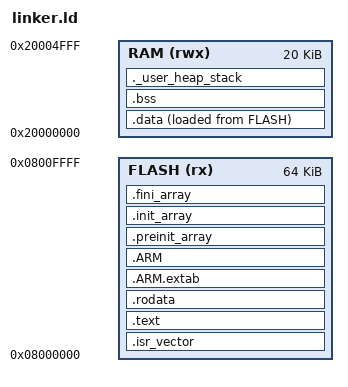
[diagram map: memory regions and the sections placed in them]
/* #######################################################################
 * linker.ld - STM32F103C8T6 链接脚本
 * #######################################################################
 *
 * 内存布局:
 *   Flash (ROM): 64KB, 起始地址 0x08000000
 *   SRAM (RAM):  20KB, 起始地址 0x20000000
 *
 * 启动流程:
 *   1. CPU 从 0x08000000 读取初始栈指针 (MSP)
 *   2. CPU 从 0x08000004 读取复位向量 (Reset_Handler)
 *   3. Reset_Handler 拷贝 .data 段, 清零 .bss 段, 跳转 main()
 *
 * ####################################################################### */

/* =======================================================================
 * 入口点定义
 * ======================================================================= */

ENTRY(Reset_Handler)

/* =======================================================================
 * 内存区域定义
 * ======================================================================= */

MEMORY
{
    FLASH (rx)  : ORIGIN = 0x08000000, LENGTH = 64K
    RAM   (rwx) : ORIGIN = 0x20000000, LENGTH = 20K
}

/* =======================================================================
 * 栈和堆配置
 * ======================================================================= */

/* 栈顶地址 (RAM 最高地址, 向下增长) */
_estack = ORIGIN(RAM) + LENGTH(RAM);

/* 栈大小 (1KB) */
__Stack_Size = 1024;
__Stack_Limit = _estack - __Stack_Size;

/* 堆大小 (0B - 不使用堆) */
__Heap_Size = 0;
_end = __Stack_Limit - __Heap_Size;

/* =======================================================================
 * 段布局定义
 * ======================================================================= */

SECTIONS
{
    /* -------------------------------------------------------------------
     * .isr_vector 段 - 中断向量表
     *
     * 必须放在 Flash 最开头 (0x08000000)
     * ------------------------------------------------------------------- */
    .isr_vector :
    {
        . = ALIGN(4);
        KEEP(*(.isr_vector))      /* 保留向量表, 不被优化掉 */
        . = ALIGN(4);
    } > FLASH

    /* -------------------------------------------------------------------
     * .text 段 - 代码和只读数据
     * ------------------------------------------------------------------- */
    .text :
    {
        . = ALIGN(4);
        *(.text)                  /* 普通代码 */
        *(.text*)                 /* 模板和内联代码 */
        *(.glue_7)                /* ARM/Thumb 互调用粘合代码 */
        *(.glue_7t)
        *(.eh_frame)              /* 异常处理帧 */

        KEEP (*(.init))           /* 初始化代码 */
        KEEP (*(.fini))           /* 清理代码 */

        . = ALIGN(4);
        _etext = .;               /* 代码段结束地址 */
    } > FLASH

    /* -------------------------------------------------------------------
     * .rodata 段 - 只读数据
     * ------------------------------------------------------------------- */
    .rodata :
    {
        . = ALIGN(4);
        *(.rodata)                /* 只读常量 */
        *(.rodata*)
        . = ALIGN(4);
    } > FLASH

    /* -------------------------------------------------------------------
     * ARM 属性段
     * ------------------------------------------------------------------- */
    .ARM.extab :
    {
        *(.ARM.extab* .gnu.linkonce.armextab.*)
    } > FLASH

    .ARM :
    {
        __exidx_start = .;
        *(.ARM.exidx*)
        __exidx_end = .;
    } > FLASH

    /* -------------------------------------------------------------------
     * .preinit_array, .init_array, .fini_array 段
     *
     * 用于 C++ 构造/析构函数 (裸机通常不使用)
     * ------------------------------------------------------------------- */
    .preinit_array :
    {
        PROVIDE_HIDDEN (__preinit_array_start = .);
        KEEP (*(.preinit_array*))
        PROVIDE_HIDDEN (__preinit_array_end = .);
    } > FLASH

    .init_array :
    {
        PROVIDE_HIDDEN (__init_array_start = .);
        KEEP (*(SORT(.init_array.*)))
        KEEP (*(.init_array*))
        PROVIDE_HIDDEN (__init_array_end = .);
    } > FLASH

    .fini_array :
    {
        PROVIDE_HIDDEN (__fini_array_start = .);
        KEEP (*(SORT(.fini_array.*)))
        KEEP (*(.fini_array*))
        PROVIDE_HIDDEN (__fini_array_end = .);
    } > FLASH

    /* -------------------------------------------------------------------
     * .data 段 - 已初始化全局/静态变量
     *
     * 存储位置:
     *   - 加载地址 (LMA): Flash 中的 _sidata
     *   - 运行地址 (VMA): RAM 中的 _sdata ~ _edata
     *
     * 启动时: startup.s 的 Reset_Handler 从 Flash 拷贝到 RAM
     * ------------------------------------------------------------------- */
    _sidata = LOADADDR(.data);    /* .data 在 Flash 中的加载地址 */

    .data :
    {
        . = ALIGN(4);
        _sdata = .;               /* .data 在 RAM 中的起始地址 */
        *(.data)                  /* 已初始化数据 */
        *(.data*)
        . = ALIGN(4);
        _edata = .;               /* .data 在 RAM 中的结束地址 */
    } > RAM AT > FLASH

    /* -------------------------------------------------------------------
     * .bss 段 - 未初始化全局/静态变量
     *
     * 只在 RAM 中, 不占 Flash 空间
     * 启动时: startup.s 的 Reset_Handler 将其清零
     * ------------------------------------------------------------------- */
    .bss :
    {
        . = ALIGN(4);
        _sbss = .;                /* .bss 起始地址 */
        *(.bss)
        *(.bss*)
        *(COMMON)
        . = ALIGN(4);
        _ebss = .;                /* .bss 结束地址 */
    } > RAM

    /* -------------------------------------------------------------------
     * 用户堆栈段 (可选)
     * ------------------------------------------------------------------- */
    ._user_heap_stack :
    {
        . = ALIGN(8);
        PROVIDE ( end = . );
        PROVIDE ( _end = . );
        . = . + __Heap_Size;
        . = . + __Stack_Size;
        . = ALIGN(8);
    } > RAM

    /* -------------------------------------------------------------------
     * 调试信息段 (不占用实际空间)
     * ------------------------------------------------------------------- */
    .debug_info     0 : { *(.debug_info .gnu.linkonce.wi.*) }
    .debug_abbrev   0 : { *(.debug_abbrev) }
    .debug_line     0 : { *(.debug_line .debug_line.* .debug_line_end) }
    .debug_frame    0 : { *(.debug_frame) }
    .debug_str      0 : { *(.debug_str) }
    .debug_loc      0 : { *(.debug_loc) }
    .debug_macinfo  0 : { *(.debug_macinfo) }
    .debug_ranges   0 : { *(.debug_ranges) }

    /* -------------------------------------------------------------------
     * 删除不需要的段
     * ------------------------------------------------------------------- */
    /DISCARD/ :
    {
        libc.a ( * )
        libm.a ( * )
        libgcc.a ( * )
    }

    /* -------------------------------------------------------------------
     * ARM 属性
     * ------------------------------------------------------------------- */
    .ARM.attributes 0 : { *(.ARM.attributes) }
}

/* #######################################################################
 * 导出符号
 * ####################################################################### */

/* 向 C 代码导出关键地址 */
PROVIDE(__stack = _estack);
PROVIDE(__stack_limit = __Stack_Limit);
